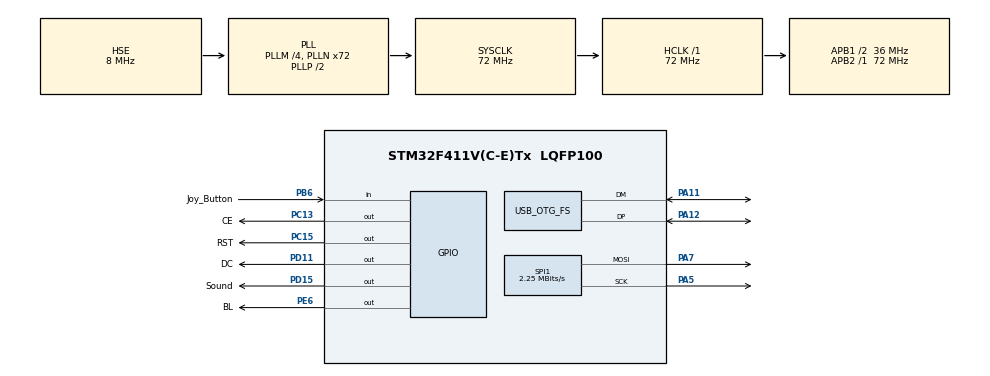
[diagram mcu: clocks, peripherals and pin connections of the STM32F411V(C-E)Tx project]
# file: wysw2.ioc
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Mcu.Family=STM32F4
Mcu.Name=STM32F411V(C-E)Tx
Mcu.Package=LQFP100
NVIC.OTG_FS_IRQn=true\:0\:0\:false\:false\:true\:false\:true
NVIC.PriorityGroup=NVIC_PRIORITYGROUP_4
NVIC.TIM3_IRQn=true\:0\:0\:false\:false\:true\:true\:true
NVIC.TIM4_IRQn=true\:0\:0\:false\:false\:true\:true\:true
PA11.Mode=Device_Only
PA11.Signal=USB_OTG_FS_DM
PA12.Mode=Device_Only
PA12.Signal=USB_OTG_FS_DP
PA5.Mode=TX_Only_Simplex_Unidirect_Master
PA5.Signal=SPI1_SCK
PA7.Mode=TX_Only_Simplex_Unidirect_Master
PA7.Signal=SPI1_MOSI
PB6.GPIO_Label=Joy_Button
PB6.Signal=GPIO_Input
PC13-ANTI_TAMP.GPIO_Label=CE
PC13-ANTI_TAMP.Signal=GPIO_Output
PC15-OSC32_OUT.GPIO_Label=RST
PC15-OSC32_OUT.Signal=GPIO_Output
PD11.GPIO_Label=DC
PD11.Signal=GPIO_Output
PD15.GPIO_Label=Sound
PD15.Signal=GPIO_Output
PE6.GPIO_Label=BL
PE6.Signal=GPIO_Output
PH0\ -\ OSC_IN.Mode=HSE-External-Oscillator
PH0\ -\ OSC_IN.Signal=RCC_OSC_IN
PH1\ -\ OSC_OUT.Mode=HSE-External-Oscillator
PH1\ -\ OSC_OUT.Signal=RCC_OSC_OUT
ProjectManager.HeapSize=0x200
ProjectManager.StackSize=0x400
ProjectManager.TargetToolchain=SW4STM32
RCC.48MHZClocksFreq_Value=48000000
RCC.AHBFreq_Value=72000000
RCC.APB1CLKDivider=RCC_HCLK_DIV2
RCC.APB1Freq_Value=36000000
RCC.APB1TimFreq_Value=72000000
RCC.APB2Freq_Value=72000000
RCC.APB2TimFreq_Value=72000000
RCC.CortexFreq_Value=72000000
RCC.HCLKFreq_Value=72000000
RCC.HSE_VALUE=8000000
RCC.HSI_VALUE=16000000
RCC.LSE_VALUE=32768
RCC.PLLM=4
RCC.PLLN=72
RCC.PLLQ=3
RCC.SYSCLKFreq_VALUE=72000000
RCC.SYSCLKSource=RCC_SYSCLKSOURCE_PLLCLK
RCC.VCOOutputFreq_Value=144000000
SPI1.BaudRatePrescaler=SPI_BAUDRATEPRESCALER_32
SPI1.CalculateBaudRate=2.25 MBits/s
SPI1.Direction=SPI_DIRECTION_2LINES
SPI1.Mode=SPI_MODE_MASTER
SPI1.VirtualType=VM_MASTER
TIM3.Period=1000-1
TIM3.Prescaler=84-1
TIM4.Period=1000-1
TIM4.Prescaler=25000-1
USB_DEVICE.CLASS_NAME_FS=CDC
USB_DEVICE.VirtualMode=Cdc
USB_DEVICE.VirtualModeFS=Cdc_FS
USB_OTG_FS.VirtualMode=Device_Only
VP_TIM3_VS_ClockSourceINT.Mode=Internal
VP_TIM4_VS_ClockSourceINT.Mode=Internal
VP_USB_DEVICE_VS_USB_DEVICE_CDC_FS.Mode=CDC_FS
board=custom

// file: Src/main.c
/* USER CODE BEGIN Header */
/**
  ******************************************************************************
  * @file           : main.c
  * @brief          : Main program body
  ******************************************************************************
  * @attention
  *
  * <h2><center>&copy; Copyright (c) 2019 STMicroelectronics.
  * All rights reserved.</center></h2>
  *
  * This software component is licensed by ST under BSD 3-Clause license,
  * the "License"; You may not use this file except in compliance with the
  * License. You may obtain a copy of the License at:
  *                        opensource.org/licenses/BSD-3-Clause
  *
  ******************************************************************************
  */
/* USER CODE END Header */

#include "main.h"
#include "usb_device.h"

/* USER CODE BEGIN Includes */
#include <morse.h>

/* USER CODE END Includes */

SPI_HandleTypeDef hspi1;

TIM_HandleTypeDef htim3;
TIM_HandleTypeDef htim4;

void SystemClock_Config(void);
static void MX_GPIO_Init(void);
static void MX_SPI1_Init(void);
static void MX_TIM4_Init(void);
static void MX_TIM3_Init(void);

int main(void)
{

  /* MCU Configuration--------------------------------------------------------*/

  /* Reset of all peripherals, Initializes the Flash interface and the Systick. */
  HAL_Init();

  /* Configure the system clock */
  SystemClock_Config();

  /* Initialize all configured peripherals */
  MX_GPIO_Init();
  MX_SPI1_Init();
  MX_TIM4_Init();
  MX_USB_DEVICE_Init();
  MX_TIM3_Init();
  /* USER CODE BEGIN 2 */
    setup();
  /* USER CODE END 2 */

  /* Infinite loop */
  /* USER CODE BEGIN WHILE */

    while (1) {
        loop();
    }
    /* USER CODE END WHILE */

}

void SystemClock_Config(void)
{
  RCC_OscInitTypeDef RCC_OscInitStruct = {0};
  RCC_ClkInitTypeDef RCC_ClkInitStruct = {0};

  /** Configure the main internal regulator output voltage
  */
  __HAL_RCC_PWR_CLK_ENABLE();
  __HAL_PWR_VOLTAGESCALING_CONFIG(PWR_REGULATOR_VOLTAGE_SCALE1);
  /** Initializes the CPU, AHB and APB busses clocks
  */
  RCC_OscInitStruct.OscillatorType = RCC_OSCILLATORTYPE_HSE;
  RCC_OscInitStruct.HSEState = RCC_HSE_ON;
  RCC_OscInitStruct.PLL.PLLState = RCC_PLL_ON;
  RCC_OscInitStruct.PLL.PLLSource = RCC_PLLSOURCE_HSE;
  RCC_OscInitStruct.PLL.PLLM = 4;
  RCC_OscInitStruct.PLL.PLLN = 72;
  RCC_OscInitStruct.PLL.PLLP = RCC_PLLP_DIV2;
  RCC_OscInitStruct.PLL.PLLQ = 3;
  if (HAL_RCC_OscConfig(&RCC_OscInitStruct) != HAL_OK)
  {
    Error_Handler();
  }
  /** Initializes the CPU, AHB and APB busses clocks
  */
  RCC_ClkInitStruct.ClockType = RCC_CLOCKTYPE_HCLK|RCC_CLOCKTYPE_SYSCLK
                              |RCC_CLOCKTYPE_PCLK1|RCC_CLOCKTYPE_PCLK2;
  RCC_ClkInitStruct.SYSCLKSource = RCC_SYSCLKSOURCE_PLLCLK;
  RCC_ClkInitStruct.AHBCLKDivider = RCC_SYSCLK_DIV1;
  RCC_ClkInitStruct.APB1CLKDivider = RCC_HCLK_DIV2;
  RCC_ClkInitStruct.APB2CLKDivider = RCC_HCLK_DIV1;

  if (HAL_RCC_ClockConfig(&RCC_ClkInitStruct, FLASH_LATENCY_2) != HAL_OK)
  {
    Error_Handler();
  }
}

static void MX_SPI1_Init(void)
{

  /* SPI1 parameter configuration*/
  hspi1.Instance = SPI1;
  hspi1.Init.Mode = SPI_MODE_MASTER;
  hspi1.Init.Direction = SPI_DIRECTION_2LINES;
  hspi1.Init.DataSize = SPI_DATASIZE_8BIT;
  hspi1.Init.CLKPolarity = SPI_POLARITY_LOW;
  hspi1.Init.CLKPhase = SPI_PHASE_1EDGE;
  hspi1.Init.NSS = SPI_NSS_SOFT;
  hspi1.Init.BaudRatePrescaler = SPI_BAUDRATEPRESCALER_32;
  hspi1.Init.FirstBit = SPI_FIRSTBIT_MSB;
  hspi1.Init.TIMode = SPI_TIMODE_DISABLE;
  hspi1.Init.CRCCalculation = SPI_CRCCALCULATION_DISABLE;
  hspi1.Init.CRCPolynomial = 10;
  if (HAL_SPI_Init(&hspi1) != HAL_OK)
  {
    Error_Handler();
  }

}

static void MX_TIM3_Init(void)
{

  TIM_ClockConfigTypeDef sClockSourceConfig = {0};
  TIM_MasterConfigTypeDef sMasterConfig = {0};

  htim3.Instance = TIM3;
  htim3.Init.Prescaler = 84-1;
  htim3.Init.CounterMode = TIM_COUNTERMODE_UP;
  htim3.Init.Period = 1000-1;
  htim3.Init.ClockDivision = TIM_CLOCKDIVISION_DIV1;
  htim3.Init.AutoReloadPreload = TIM_AUTORELOAD_PRELOAD_DISABLE;
  if (HAL_TIM_Base_Init(&htim3) != HAL_OK)
  {
    Error_Handler();
  }
  sClockSourceConfig.ClockSource = TIM_CLOCKSOURCE_INTERNAL;
  if (HAL_TIM_ConfigClockSource(&htim3, &sClockSourceConfig) != HAL_OK)
  {
    Error_Handler();
  }
  sMasterConfig.MasterOutputTrigger = TIM_TRGO_RESET;
  sMasterConfig.MasterSlaveMode = TIM_MASTERSLAVEMODE_DISABLE;
  if (HAL_TIMEx_MasterConfigSynchronization(&htim3, &sMasterConfig) != HAL_OK)
  {
    Error_Handler();
  }

}

static void MX_TIM4_Init(void)
{

  TIM_ClockConfigTypeDef sClockSourceConfig = {0};
  TIM_MasterConfigTypeDef sMasterConfig = {0};

  htim4.Instance = TIM4;
  htim4.Init.Prescaler = 25000-1;
  htim4.Init.CounterMode = TIM_COUNTERMODE_UP;
  htim4.Init.Period = 1000-1;
  htim4.Init.ClockDivision = TIM_CLOCKDIVISION_DIV1;
  htim4.Init.AutoReloadPreload = TIM_AUTORELOAD_PRELOAD_DISABLE;
  if (HAL_TIM_Base_Init(&htim4) != HAL_OK)
  {
    Error_Handler();
  }
  sClockSourceConfig.ClockSource = TIM_CLOCKSOURCE_INTERNAL;
  if (HAL_TIM_ConfigClockSource(&htim4, &sClockSourceConfig) != HAL_OK)
  {
    Error_Handler();
  }
  sMasterConfig.MasterOutputTrigger = TIM_TRGO_RESET;
  sMasterConfig.MasterSlaveMode = TIM_MASTERSLAVEMODE_DISABLE;
  if (HAL_TIMEx_MasterConfigSynchronization(&htim4, &sMasterConfig) != HAL_OK)
  {
    Error_Handler();
  }

}

static void MX_GPIO_Init(void)
{
  GPIO_InitTypeDef GPIO_InitStruct = {0};

  /* GPIO Ports Clock Enable */
  __HAL_RCC_GPIOE_CLK_ENABLE();
  __HAL_RCC_GPIOC_CLK_ENABLE();
  __HAL_RCC_GPIOH_CLK_ENABLE();
  __HAL_RCC_GPIOA_CLK_ENABLE();
  __HAL_RCC_GPIOD_CLK_ENABLE();
  __HAL_RCC_GPIOB_CLK_ENABLE();

  /*Configure GPIO pin Output Level */
  HAL_GPIO_WritePin(BL_GPIO_Port, BL_Pin, GPIO_PIN_RESET);

  /*Configure GPIO pin Output Level */
  HAL_GPIO_WritePin(GPIOC, CE_Pin|RST_Pin, GPIO_PIN_RESET);

  /*Configure GPIO pin Output Level */
  HAL_GPIO_WritePin(GPIOD, DC_Pin|Sound_Pin, GPIO_PIN_RESET);

  /*Configure GPIO pin : BL_Pin */
  GPIO_InitStruct.Pin = BL_Pin;
  GPIO_InitStruct.Mode = GPIO_MODE_OUTPUT_PP;
  GPIO_InitStruct.Pull = GPIO_NOPULL;
  GPIO_InitStruct.Speed = GPIO_SPEED_FREQ_LOW;
  HAL_GPIO_Init(BL_GPIO_Port, &GPIO_InitStruct);

  /*Configure GPIO pins : CE_Pin RST_Pin */
  GPIO_InitStruct.Pin = CE_Pin|RST_Pin;
  GPIO_InitStruct.Mode = GPIO_MODE_OUTPUT_PP;
  GPIO_InitStruct.Pull = GPIO_NOPULL;
  GPIO_InitStruct.Speed = GPIO_SPEED_FREQ_LOW;
  HAL_GPIO_Init(GPIOC, &GPIO_InitStruct);

  /*Configure GPIO pins : DC_Pin Sound_Pin */
  GPIO_InitStruct.Pin = DC_Pin|Sound_Pin;
  GPIO_InitStruct.Mode = GPIO_MODE_OUTPUT_PP;
  GPIO_InitStruct.Pull = GPIO_NOPULL;
  GPIO_InitStruct.Speed = GPIO_SPEED_FREQ_LOW;
  HAL_GPIO_Init(GPIOD, &GPIO_InitStruct);

  /*Configure GPIO pin : Joy_Button_Pin */
  GPIO_InitStruct.Pin = Joy_Button_Pin;
  GPIO_InitStruct.Mode = GPIO_MODE_INPUT;
  GPIO_InitStruct.Pull = GPIO_NOPULL;
  HAL_GPIO_Init(Joy_Button_GPIO_Port, &GPIO_InitStruct);

}

void Error_Handler(void)
{
}

/************************ (C) COPYRIGHT STMicroelectronics *****END OF FILE****/
